# STM32H523xx register map
File version: 1.0
Registers are 32-bit, read-write, reset 0x0 unless marked. A register's access mark holds for its fields unless they carry their own. Offsets are from the block's base; [hi:lo] are bit positions.

## CEC — Consumer Electronics Control
Base 0x40007000
Same registers: CEC_S 0x50007000
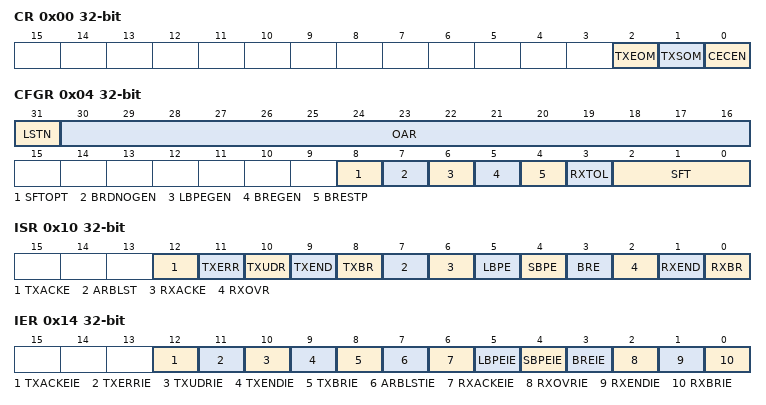
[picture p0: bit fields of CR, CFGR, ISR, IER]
0x00 CR — CEC control register
  [2] TXEOM — CEC Tx End Of Message
  [1] TXSOM — CEC Tx Start Of Message
  [0] CECEN — CEC Enable
0x04 CFGR — CEC configuration register
  [31] LSTN — CEC Listen mode
  [30:16] OAR — CEC Own Address
  [8] SFTOPT — CEC Signal Free Time optional
  [7] BRDNOGEN — CEC Broadcast No error generation
  [6] LBPEGEN — CEC Long Bit Period Error generation
  [5] BREGEN — CEC Bit Rising Error generation
  [4] BRESTP — CEC Rx Stop
  [3] RXTOL — CEC Tolerance
  [2:0] SFT — CEC Signal Free Time
0x08 TXDR — CEC Tx data register
  [7:0] TXD — CEC Tx Data
0x0C RXDR — CEC Rx Data Register
  [7:0] RXD — CEC Rx Data
0x10 ISR — CEC Interrupt and Status Register
  [12] TXACKE — CEC Tx Missing Acknowledge
  [11] TXERR — CEC Tx-Error
  [10] TXUDR — CEC Tx-Buffer Underrun
  [9] TXEND — CEC End of Transmission
  [8] TXBR — CEC Tx Byte Request
  [7] ARBLST — CEC Arbitration Lost
  [6] RXACKE — CEC Rx Missing Acknowledge
  [5] LBPE — CEC Rx Long Bit period Error
  [4] SBPE — CEC Rx Short Bit period Error
  [3] BRE — CEC Rx Bit Rising Error
  [2] RXOVR — CEC Rx-Overrun
  [1] RXEND — CEC End Of Reception
  [0] RXBR — CEC Rx-Byte Received
0x14 IER — CEC interrupt enable register
  [12] TXACKEIE — CEC Tx Missing Acknowledge IT Enable
  [11] TXERRIE — CEC Tx-Error IT Enable
  [10] TXUDRIE — CEC Tx-Buffer Underrun IT Enable
  [9] TXENDIE — CEC End of Transmission IT Enable
  [8] TXBRIE — CEC Tx Byte Request IT Enable
  [7] ARBLSTIE — CEC Arbitration Lost IT Enable
  [6] RXACKEIE — CEC Rx Missing Acknowledge IT Enable
  [5] LBPEIE — CEC Rx Long Bit period Error IT Enable
  [4] SBPEIE — CEC Rx Short Bit period Error IT Enable
  [3] BREIE — CEC Rx Bit Rising Error IT Enable
  [2] RXOVRIE — CEC Rx-Overrun IT Enable
  [1] RXENDIE — CEC End Of Reception IT Enable
  [0] RXBRIE — CEC Rx-Byte Received IT Enable

## DTS
Base 0x40008C00
Same registers: DTS_S 0x50008C00
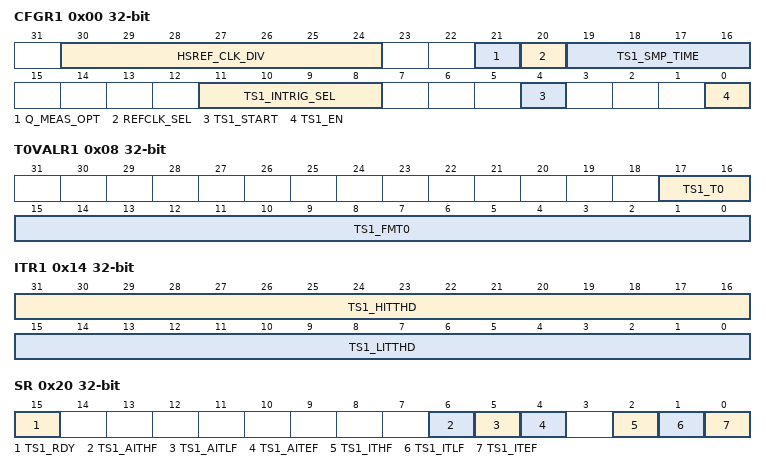
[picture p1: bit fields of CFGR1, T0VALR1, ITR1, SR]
0x00 CFGR1 — DTS configuration register
  [30:24] HSREF_CLK_DIV — High Speed Clock Divider Ratio [6:0]
  [21] Q_MEAS_OPT — Quick measure option bit
  [20] REFCLK_SEL — Reference Clock Selection
  [19:16] TS1_SMP_TIME — Sample time [3:0] for DTS
  [11:8] TS1_INTRIG_SEL — Input triggers selection bits [3:0] for DTS
  [4] TS1_START — Proceed to a frequency measurement on DTS
  [0] TS1_EN — DTS Enable
0x08 T0VALR1 — DTS T0 Value register
  [17:16] TS1_T0 — Engineering value of the DTSerature T0 for DTS
  [15:0] TS1_FMT0 — Engineering value of the measured frequency at T0 for DTS
0x10 RAMPVALR — DTS Ramp value register
  [15:0] TS1_RAMP_COEFF — Engineering value of the ramp coefficient for DTS
0x14 ITR1 — DTS Interrupt threshold register
  [31:16] TS1_HITTHD — High interrupt threshold[15:0] for DTS
  [15:0] TS1_LITTHD — Low interrupt threshold[15:0] for DTS
0x1C DR — DTS data register
  [15:0] TS1_MFREQ — Measured Frequency[15:0] for DTS
0x20 SR — DTS status register
  [15] TS1_RDY — DTS ready flag
  [6] TS1_AITHF — Asynchronous interrupt flag for high threshold for DTS
  [5] TS1_AITLF — Asynchronous interrupt flag for low threshold for DTS
  [4] TS1_AITEF — Asynchronous interrupt flag for end of measure for DTS
  [2] TS1_ITHF — Interrupt flag for high threshold for DTS
  [1] TS1_ITLF — Interrupt flag for low threshold for DTS
  [0] TS1_ITEF — Interrupt flag for end of measure for DTS
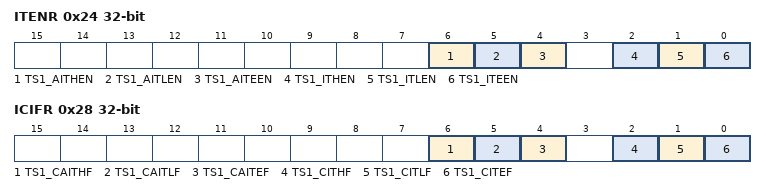
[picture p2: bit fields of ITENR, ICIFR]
0x24 ITENR — DTS Interrupt enable register
  [6] TS1_AITHEN — Enable asynchronous interrupt flag for high threshold for DTS
  [5] TS1_AITLEN — Enable Asynchronous interrupt flag for low threshold for DTS
  [4] TS1_AITEEN — Enable asynchronous interrupt flag for end of measure for DTS
  [2] TS1_ITHEN — Enable interrupt flag for high threshold for DTS
  [1] TS1_ITLEN — Enable interrupt flag for low threshold for DTS
  [0] TS1_ITEEN — Enable interrupt flag for end of measure for DTS
0x28 ICIFR — DTS Clear Interrupt flag register
  [6] TS1_CAITHF — Clear the asynchronous IT flag for high threshold on DTS
  [5] TS1_CAITLF — Clear the asynchronous IT flag for low threshold for DTS
  [4] TS1_CAITEF — Clear the asynchronous IT flag for End Of Measure for DTS
  [2] TS1_CITHF — Clear the IT flag for high threshold on DTS
  [1] TS1_CITLF — Clear the IT flag for low threshold for DTS
  [0] TS1_CITEF — Clear the IT flag for End Of Measure for DTS
0x2C OR — DTS option register 1
